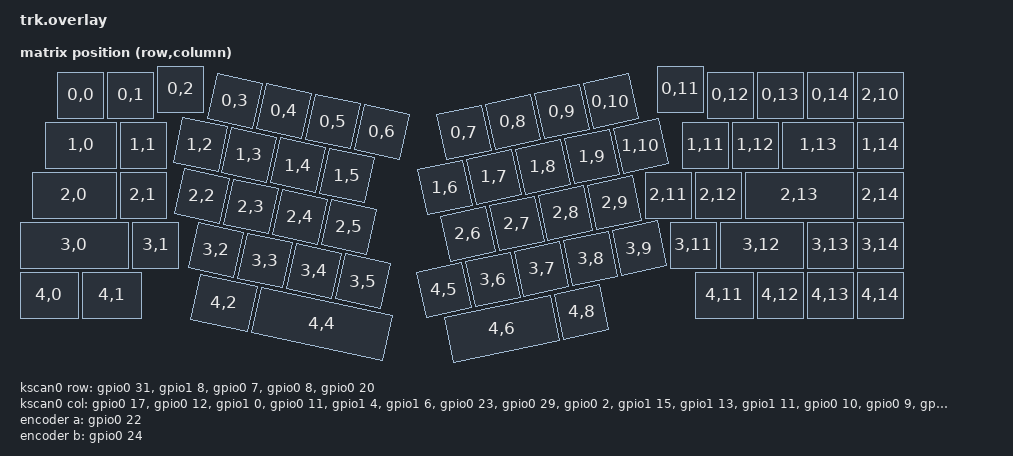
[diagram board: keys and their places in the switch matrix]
#include <dt-bindings/zmk/matrix_transform.h>
#include <physical_layouts.dtsi>

/ {
    chosen {
        zmk,kscan = &kscan0;
		zmk,physical-layout = &trk_default_layout;
    };

	default_transform: matrix_transform {
		compatible = "zmk,matrix-transform";
		rows = <5>;
		columns = <15>;
		map = <
			RC(0,0) RC(0,1) RC(0,2) RC(0,3) RC(0,4) RC(0,5) RC(0,6) RC(0,7) RC(0,8) RC(0,9) RC(0,10) RC(0,11) RC(0,12) RC(0,13) RC(0,14)
			RC(1,0) RC(1,1) RC(1,2) RC(1,3) RC(1,4) RC(1,5) RC(1,6) RC(1,7) RC(1,8) RC(1,9) RC(1,10) RC(1,11) RC(1,12) RC(1,13) RC(1,14)
			RC(2,0) RC(2,1) RC(2,2) RC(2,3) RC(2,4) RC(2,5) RC(2,6) RC(2,7) RC(2,8) RC(2,9) RC(2,10) RC(2,11) RC(2,12) RC(2,13) RC(2,14)
			RC(3,0) RC(3,1) RC(3,2) RC(3,3) RC(3,4) RC(3,5) RC(3,6) RC(3,7) RC(3,8) RC(3,9)          RC(3,11) RC(3,12) RC(3,13) RC(3,14)
			RC(4,0) RC(4,1) RC(4,2)         RC(4,4) RC(4,5) RC(4,6)         RC(4,8)                  RC(4,11) RC(4,12) RC(4,13) RC(4,14)
		>;
	};

	trk_default_layout: trk_default_layout {
		compatible = "zmk,physical-layout";
		display-name = "TRK Default";
		kscan = <&kscan0>;
		transform = <&default_transform>;
		keys = <
			/* Row 0 */
			&key_physical_attrs 100 100 175 50 0 0 0  &key_physical_attrs 100 100 275 50 0 0 0  &key_physical_attrs 100 100 375 38 0 0 0  &key_physical_attrs 100 100 475 50 1200 475 150  &key_physical_attrs 100 100 575 50 1200 475 150  &key_physical_attrs 100 100 675 50 1200 475 150  &key_physical_attrs 100 100 775 50 1200 475 150  &key_physical_attrs 100 100 945 50 (-1200) 1350 150  &key_physical_attrs 100 100 1045 50 (-1200) 1350 150  &key_physical_attrs 100 100 1145 50 (-1200) 1350 150  &key_physical_attrs 100 100 1245 50 (-1200) 1350 150  &key_physical_attrs 100 100 1375 38 0 0 0  &key_physical_attrs 100 100 1475 50 0 0 0  &key_physical_attrs 100 100 1575 50 0 0 0  &key_physical_attrs 100 100 1675 50 0 0 0
			/* Row 1 */
			&key_physical_attrs 150 100 150 150 0 0 0  &key_physical_attrs 100 100 300 150 0 0 0  &key_physical_attrs 100 100 425 150 1200 475 150  &key_physical_attrs 100 100 525 150 1200 475 150  &key_physical_attrs 100 100 625 150 1200 475 150  &key_physical_attrs 100 100 725 150 1200 475 150  &key_physical_attrs 100 100 885 150 (-1200) 1350 150  &key_physical_attrs 100 100 985 150 (-1200) 1350 150  &key_physical_attrs 100 100 1085 150 (-1200) 1350 150  &key_physical_attrs 100 100 1185 150 (-1200) 1350 150  &key_physical_attrs 100 100 1285 150 (-1200) 1350 150  &key_physical_attrs 100 100 1425 150 0 0 0  &key_physical_attrs 100 100 1525 150 0 0 0  &key_physical_attrs 150 100 1625 150 0 0 0  &key_physical_attrs 100 100 1775 150 0 0 0
			/* Row 2 */
			&key_physical_attrs 175 100 125 250 0 0 0  &key_physical_attrs 100 100 300 250 0 0 0  &key_physical_attrs 100 100 450 250 1200 475 150  &key_physical_attrs 100 100 550 250 1200 475 150  &key_physical_attrs 100 100 650 250 1200 475 150  &key_physical_attrs 100 100 750 250 1200 475 150  &key_physical_attrs 100 100 910 250 (-1200) 1350 150  &key_physical_attrs 100 100 1010 250 (-1200) 1350 150  &key_physical_attrs 100 100 1110 250 (-1200) 1350 150  &key_physical_attrs 100 100 1210 250 (-1200) 1350 150  &key_physical_attrs 100 100 1775 50 0 0 0  &key_physical_attrs 100 100 1350 250 0 0 0  &key_physical_attrs 100 100 1450 250 0 0 0  &key_physical_attrs 225 100 1550 250 0 0 0  &key_physical_attrs 100 100 1775 250 0 0 0
			/* Row 3 */
			&key_physical_attrs 225 100 100 350 0 0 0  &key_physical_attrs 100 100 325 350 0 0 0  &key_physical_attrs 100 100 500 350 1200 475 150  &key_physical_attrs 100 100 600 350 1200 475 150  &key_physical_attrs 100 100 700 350 1200 475 150  &key_physical_attrs 100 100 800 350 1200 475 150  &key_physical_attrs 100 100 945 350 (-1200) 1350 175  &key_physical_attrs 100 100 1045 350 (-1200) 1350 175  &key_physical_attrs 100 100 1145 350 (-1200) 1350 175  &key_physical_attrs 100 100 1245 350 (-1200) 1350 175  &key_physical_attrs 100 100 1400 350 0 0 0  &key_physical_attrs 175 100 1500 350 0 0 0  &key_physical_attrs 100 100 1675 350 0 0 0  &key_physical_attrs 100 100 1775 350 0 0 0
			/* Row 4 */
			&key_physical_attrs 125 100 100 450 0 0 0  &key_physical_attrs 125 100 225 450 0 0 0  &key_physical_attrs 125 100 525 450 1200 475 150  &key_physical_attrs 275 100 650 450 1200 475 150  &key_physical_attrs 100 100 845 350 (-1200) 1350 175  &key_physical_attrs 225 100 875 450 (-1200) 1350 150  &key_physical_attrs 100 100 1100 450 (-1200) 1350 150  &key_physical_attrs 125 100 1450 450 0 0 0  &key_physical_attrs 100 100 1575 450 0 0 0  &key_physical_attrs 100 100 1675 450 0 0 0  &key_physical_attrs 100 100 1775 450 0 0 0
		>;
	};

    kscan0: kscan {
        compatible = "zmk,kscan-gpio-matrix";
        label = "KSCAN";
        diode-direction = "col2row";

        col-gpios
            = <&gpio0    17 GPIO_ACTIVE_HIGH>
            , <&gpio0    12 GPIO_ACTIVE_HIGH>
            , <&gpio1     0 GPIO_ACTIVE_HIGH>
            , <&gpio0    11 GPIO_ACTIVE_HIGH>
            , <&gpio1     4 GPIO_ACTIVE_HIGH>
            , <&gpio1     6 GPIO_ACTIVE_HIGH>
            , <&gpio0    23 GPIO_ACTIVE_HIGH>
            , <&gpio0    29 GPIO_ACTIVE_HIGH>
            , <&gpio0     2 GPIO_ACTIVE_HIGH>
            , <&gpio1    15 GPIO_ACTIVE_HIGH>
            , <&gpio1    13 GPIO_ACTIVE_HIGH>
            , <&gpio1    11 GPIO_ACTIVE_HIGH>
            , <&gpio0    10 GPIO_ACTIVE_HIGH>
            , <&gpio0     9 GPIO_ACTIVE_HIGH>
            , <&gpio0    21 GPIO_ACTIVE_HIGH>
            ;

        row-gpios
            = <&gpio0    31 (GPIO_ACTIVE_HIGH | GPIO_PULL_DOWN)>
            , <&gpio1     8 (GPIO_ACTIVE_HIGH | GPIO_PULL_DOWN)>
            , <&gpio0     7 (GPIO_ACTIVE_HIGH | GPIO_PULL_DOWN)>
            , <&gpio0     8 (GPIO_ACTIVE_HIGH | GPIO_PULL_DOWN)>
            , <&gpio0    20 (GPIO_ACTIVE_HIGH | GPIO_PULL_DOWN)>
            ;
    };

    encoder: encoder {
        compatible = "alps,ec11";
        label = "ENCODER";
        a-gpios = <&gpio0 22 (GPIO_ACTIVE_HIGH | GPIO_PULL_UP)>;
        b-gpios = <&gpio0 24 (GPIO_ACTIVE_HIGH | GPIO_PULL_UP)>;
        resolution = <2>;
    };

    sensors {
        compatible = "zmk,keymap-sensors";
        sensors = <&encoder>;
    };
};

